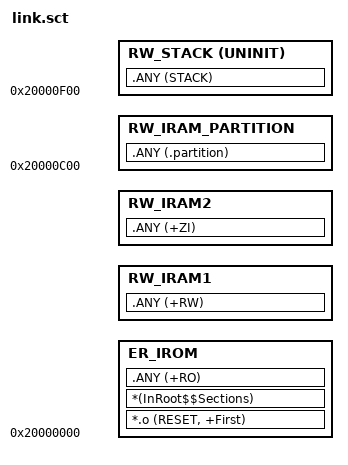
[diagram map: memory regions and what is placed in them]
; load region size_region
LR_IROM 0x20000000
{
  ; load address = execution address
  ER_IROM 0x20000000              
  {
   *.o (RESET, +First)
   *(InRoot$$Sections)
   .ANY (+RO)
  }
	
  ; RW data
  RW_IRAM1 +0
  {
   .ANY (+RW)
  }
	
  RW_IRAM2 +0
  {
   .ANY (+ZI)
  }
	
  RW_STACK 0x20000000 + 0x1000 - 0x100 UNINIT
  {
   .ANY (STACK)
  }
}

LR_IROM2 0x20000000 + 0x400*3
{
  ; load address = execution address
	
  RW_IRAM_PARTITION +0
  {
   .ANY (.partition)
  }
	
}
